VERSION ""

NS_ :

BS_:

BU_ ECU1 ECU2 Display

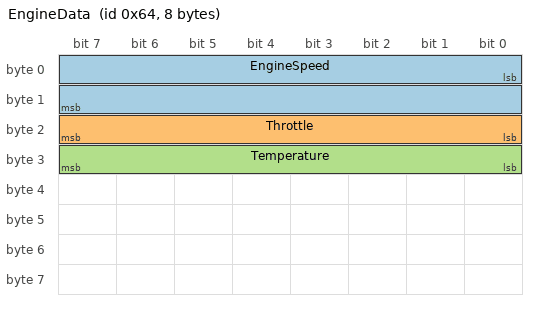
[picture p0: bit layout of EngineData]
BO_ 100 EngineData: 8 ECU1
 SG_ EngineSpeed : 0|16@1+ (0.25,0) [0|16383.75] "rpm" ECU2,Display
 SG_ Throttle : 16|8@1+ (0.392157,0) [0|100] "%" ECU2,Display
 SG_ Temperature : 24|8@1+ (1,-40) [-40|215] "degC" Display

BO_ 200 VehicleSpeed: 2 ECU2
 SG_ Speed : 0|16@1+ (0.01,0) [0|655.35] "km/h" Display

BO_ 300 GearboxStatus: 1 ECU2
 SG_ GearPosition : 0|3@1+ (1,0) [0|7] "" Display
 SG_ Clutch : 3|1@1+ (1,0) [0|1] "" Display

CM_ BU_ ECU1 "Engine Control Unit";
CM_ BU_ ECU2 "Transmission Control Unit";
CM_ BU_ Display "Dashboard Display";

CM_ BO_ 100 "Engine operating parameters";
CM_ SG_ 100 EngineSpeed "Current engine rotation speed";
CM_ SG_ 100 Throttle "Throttle position percentage";
CM_ SG_ 100 Temperature "Engine coolant temperature";

VAL_ 300 GearPosition 0 "Park" 1 "Reverse" 2 "Neutral" 3 "Drive" 4 "Sport" ;
VAL_ 300 Clutch 0 "Disengaged" 1 "Engaged" ;
